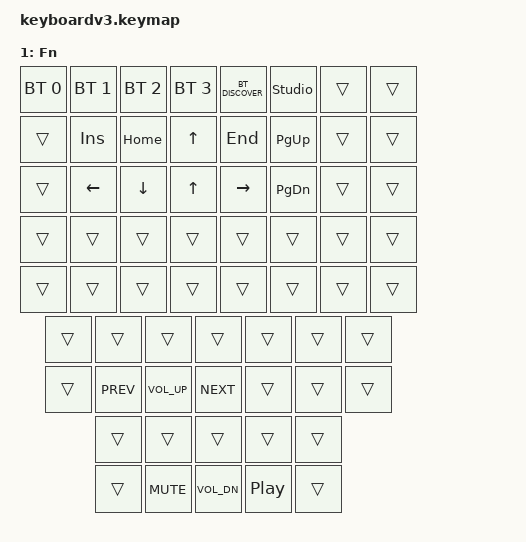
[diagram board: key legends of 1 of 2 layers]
#include <behaviors.dtsi>
#include <dt-bindings/zmk/keys.h>
#include <dt-bindings/zmk/bt.h>
#include <dt-bindings/zmk/studio.h>  // necessário para &studio_unlock

/ {
    keymap {
        compatible = "zmk,keymap";

        default_layer {
            display-name = "Base";
            bindings = <
                ...
            >;
        };

        fn_layer {
            display-name = "Fn";
            bindings = <
                // Row 0 (canto superior direito: pairing + studio unlock)
                &bt BT_SEL 0  &bt BT_SEL 1  &bt BT_SEL 2  &bt BT_SEL 3  &bt BT_DISCOVER  &studio_unlock  &trans  &trans

                // Row 1
                &trans &kp INS  &kp HOME &kp UP   &kp END   &kp PG_UP &trans &trans
                &trans &kp LEFT &kp DOWN &kp UP   &kp RIGHT &kp PG_DN &trans &trans

                // Row 2
                &trans &trans &trans &trans &trans &trans &trans &trans
                &trans &trans &trans &trans &trans &trans &trans &trans

                // Row 3
                &trans &trans &trans &trans &trans &trans &trans
                &trans &kp C_PREV &kp C_VOL_UP &kp C_NEXT &trans &trans &trans

                // Row 4
                &trans &trans &trans &trans &trans
                &trans &kp C_MUTE &kp C_VOL_DN &kp C_PP &trans
            >;
        };
    };
};
